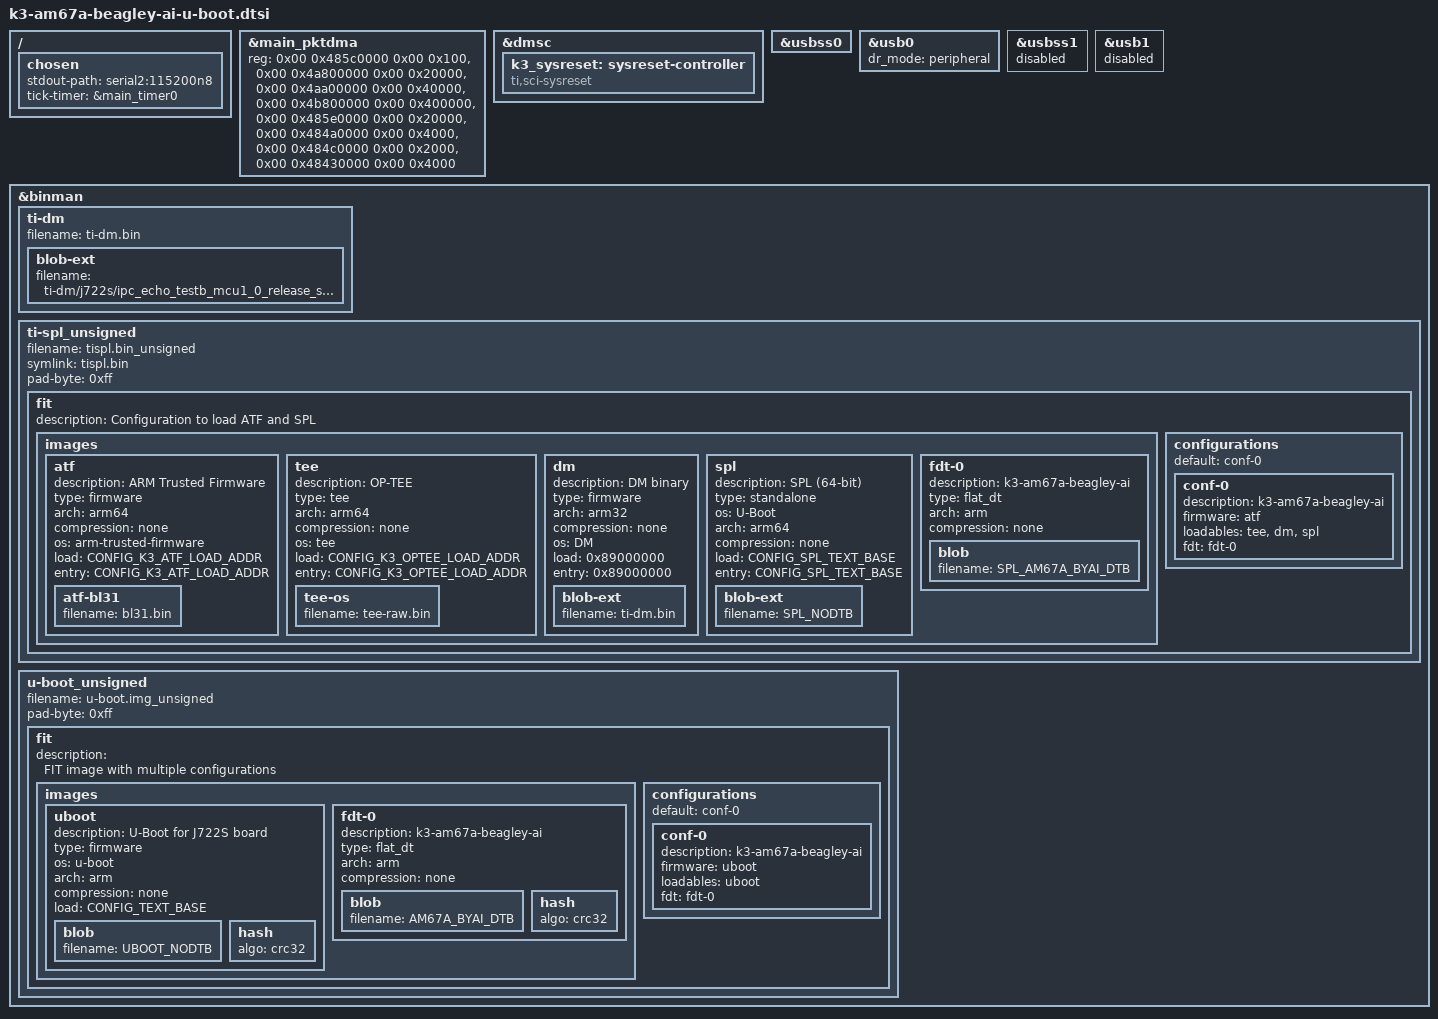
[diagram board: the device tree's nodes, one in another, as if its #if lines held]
// SPDX-License-Identifier: GPL-2.0
/*
 * https://beagley-ai.org/
 *
 * Copyright (C) 2024 Texas Instruments Incorporated - https://www.ti.com/
 * Copyright (C) 2024 Robert Nelson, BeagleBoard.org Foundation
 */

#include "k3-j722s-binman.dtsi"

/ {
	chosen {
		stdout-path = "serial2:115200n8";
		tick-timer = &main_timer0;
	};
};

&main_pktdma {
	reg = <0x00 0x485c0000 0x00 0x100>,
	      <0x00 0x4a800000 0x00 0x20000>,
	      <0x00 0x4aa00000 0x00 0x40000>,
	      <0x00 0x4b800000 0x00 0x400000>,
	      <0x00 0x485e0000 0x00 0x20000>,
	      <0x00 0x484a0000 0x00 0x4000>,
	      <0x00 0x484c0000 0x00 0x2000>,
	      <0x00 0x48430000 0x00 0x4000>;
	reg-names = "gcfg", "rchanrt", "tchanrt", "ringrt",
		    "cfg", "tchan", "rchan", "rflow";
};

&dmsc {
	bootph-pre-ram;
	k3_sysreset: sysreset-controller {
		compatible = "ti,sci-sysreset";
		bootph-pre-ram;
	};
};

&usbss0 {
	bootph-pre-ram;
};

&usb0 {
	dr_mode = "peripheral";
	bootph-pre-ram;
};

&usbss1 {
	status = "disabled";
};

&usb1 {
	status = "disabled";
};

#ifdef CONFIG_TARGET_AM67A_A53_BEAGLEYAI

#define SPL_NODTB "spl/u-boot-spl-nodtb.bin"
#define SPL_AM67A_BYAI_DTB "spl/dts/ti/k3-am67a-beagley-ai.dtb"

#define UBOOT_NODTB "u-boot-nodtb.bin"
#define AM67A_BYAI_DTB "dts/upstream/src/arm64/ti/k3-am67a-beagley-ai.dtb"

&binman {
	ti-dm {
		filename = "ti-dm.bin";
		blob-ext {
			filename = "ti-dm/j722s/ipc_echo_testb_mcu1_0_release_strip.xer5f";
		};
	};

	ti-spl_unsigned {
		filename = "tispl.bin_unsigned";
		symlink = "tispl.bin";
		pad-byte = <0xff>;

		fit {
			description = "Configuration to load ATF and SPL";
			#address-cells = <1>;

			images {

				atf {
					description = "ARM Trusted Firmware";
					type = "firmware";
					arch = "arm64";
					compression = "none";
					os = "arm-trusted-firmware";
					load = <CONFIG_K3_ATF_LOAD_ADDR>;
					entry = <CONFIG_K3_ATF_LOAD_ADDR>;
					atf-bl31 {
						filename = "bl31.bin";
					};
				};

				tee {
					description = "OP-TEE";
					type = "tee";
					arch = "arm64";
					compression = "none";
					os = "tee";
					load = <CONFIG_K3_OPTEE_LOAD_ADDR>;
					entry = <CONFIG_K3_OPTEE_LOAD_ADDR>;
					tee-os {
						filename = "tee-raw.bin";
					};
				};

				dm {
					description = "DM binary";
					type = "firmware";
					arch = "arm32";
					compression = "none";
					os = "DM";
					load = <0x89000000>;
					entry = <0x89000000>;
					blob-ext {
						filename = "ti-dm.bin";
					};
				};

				spl {
					description = "SPL (64-bit)";
					type = "standalone";
					os = "U-Boot";
					arch = "arm64";
					compression = "none";
					load = <CONFIG_SPL_TEXT_BASE>;
					entry = <CONFIG_SPL_TEXT_BASE>;
					blob-ext {
						filename = SPL_NODTB;
					};
				};

				fdt-0 {
					description = "k3-am67a-beagley-ai";
					type = "flat_dt";
					arch = "arm";
					compression = "none";
					blob {
						filename = SPL_AM67A_BYAI_DTB;
					};
				};
			};

			configurations {
				default = "conf-0";

				conf-0 {
					description = "k3-am67a-beagley-ai";
					firmware = "atf";
					loadables = "tee", "dm", "spl";
					fdt = "fdt-0";
				};
			};
		};
	};

	u-boot_unsigned {
		filename = "u-boot.img_unsigned";
		pad-byte = <0xff>;

		fit {
			description = "FIT image with multiple configurations";

			images {
				uboot {
					description = "U-Boot for J722S board";
					type = "firmware";
					os = "u-boot";
					arch = "arm";
					compression = "none";
					load = <CONFIG_TEXT_BASE>;
					blob {
						filename = UBOOT_NODTB;
					};
					hash {
						algo = "crc32";
					};
				};

				fdt-0 {
					description = "k3-am67a-beagley-ai";
					type = "flat_dt";
					arch = "arm";
					compression = "none";
					blob {
						filename = AM67A_BYAI_DTB;
					};
					hash {
						algo = "crc32";
					};
				};
			};

			configurations {
				default = "conf-0";

				conf-0 {
					description = "k3-am67a-beagley-ai";
					firmware = "uboot";
					loadables = "uboot";
					fdt = "fdt-0";
				};
			};
		};
	};
};

#endif
